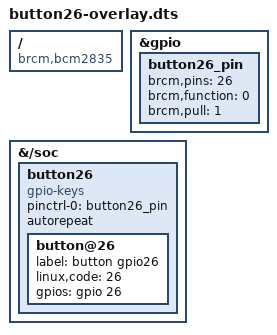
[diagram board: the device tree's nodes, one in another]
/dts-v1/;
/plugin/;

/ {
    compatible = "brcm,bcm2835", "brcm,bcm2708", "brcm,bcm2709";

    fragment@0 {
        target = <&gpio>;
        __overlay__ {
            button26_pin: button26_pin {
                brcm,pins = <26>;     /* gpio26 */
                brcm,function = <0>; /* input */
                brcm,pull = <1>;     /* pull-down */
            };
        };
    };

    fragment@1 {
    target-path = "/soc";
        __overlay__ {
            button26: button26 {
                compatible = "gpio-keys";
                #address-cells = <1>;
                #size-cells = <0>;
                pinctrl-names = "default";
                pinctrl-0 = <&button26_pin>;
                status = "okay";
                autorepeat;

                button@26 {
                    label = "button gpio26";
                    linux,code = <26>;
                    gpios = <&gpio 26 0>;
                };
            };
        };
    };
};

